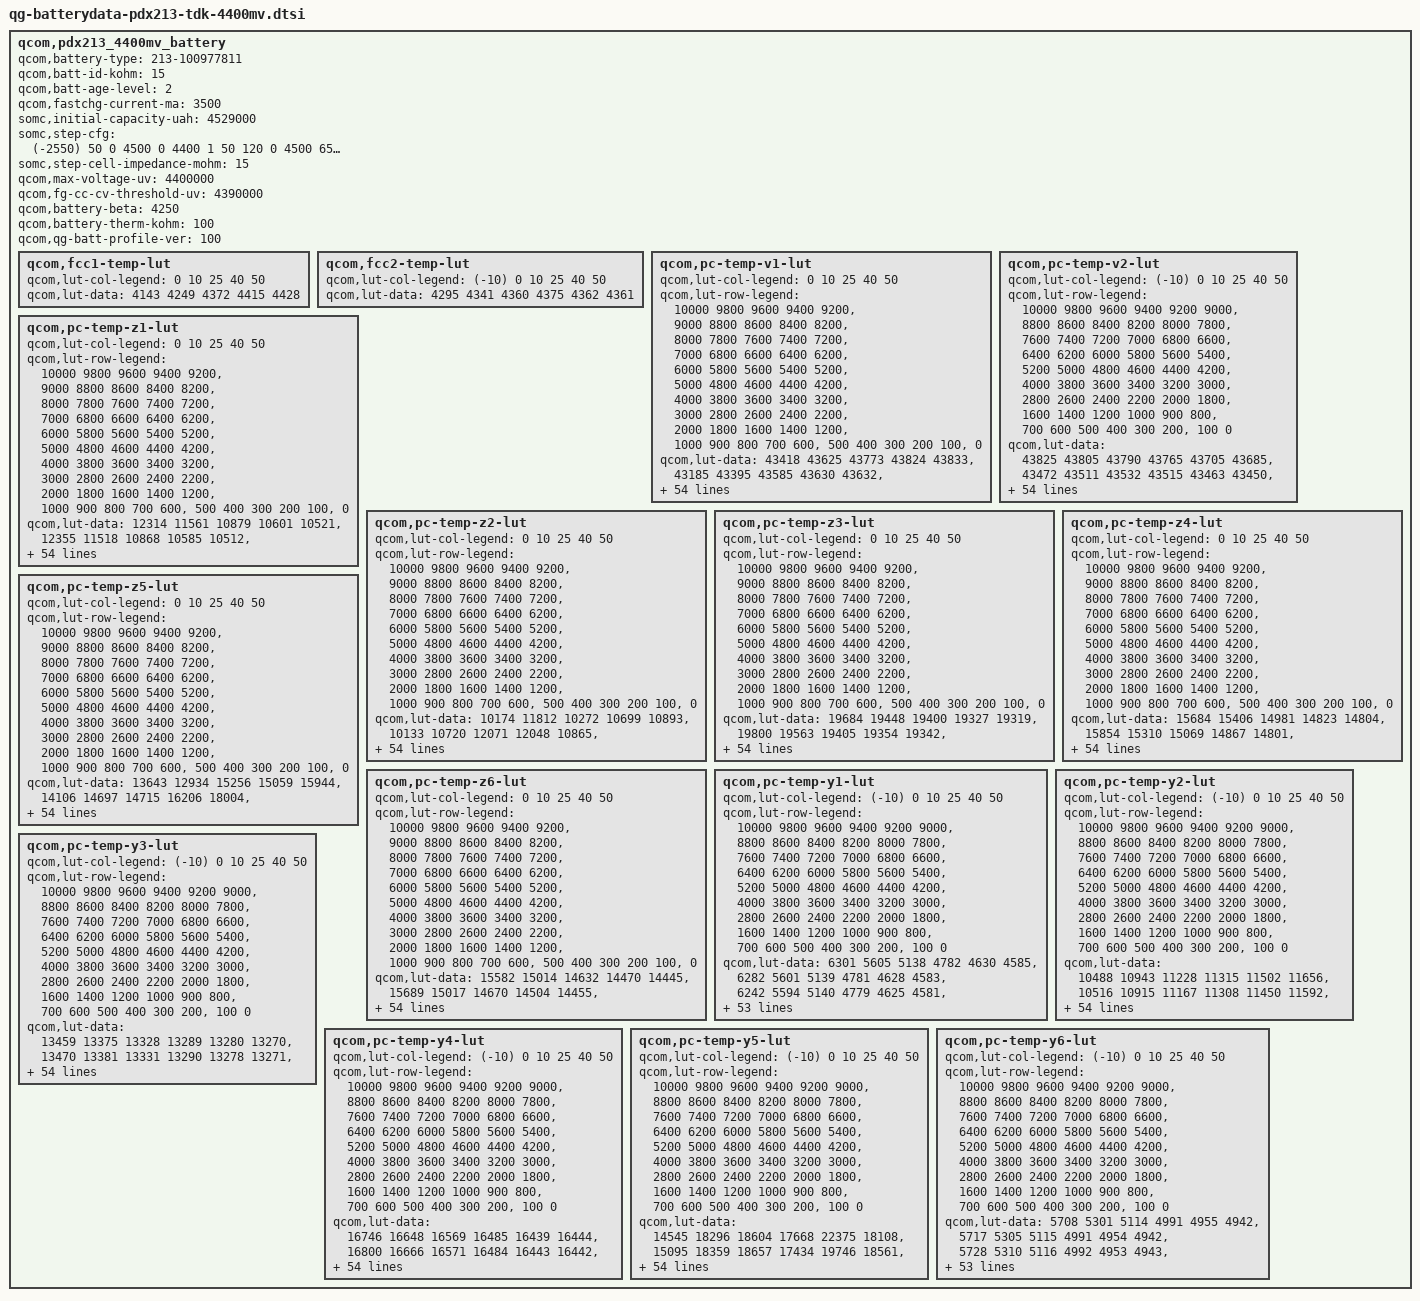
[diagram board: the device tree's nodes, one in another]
qcom,pdx213_4400mv_battery {
	/* Added or Modified by SOMC */
	qcom,battery-type = "213-100977811";
	qcom,batt-id-kohm = <15>;
	qcom,batt-age-level = <2>;
	qcom,fastchg-current-ma = <3500>;
	somc,initial-capacity-uah = <4529000>;
	somc,step-cfg = <
		(-2550) 50    0 4500    0 4400 1
		   50  120    0 4500  650 4400 2
		  120  150    0 4100 1950 4400 3
		  120  150 4100 4200 1500 4400 3
		  120  150 4200 4300 1300 4400 3
		  120  150 4300 4500  800 4400 3
		  150  200    0 4100 2400 4400 3
		  150  200 4100 4200 1950 4400 3
		  150  200 4200 4300 1750 4400 3
		  150  200 4300 4500 1050 4400 3
		  200  450    0 4200 3900 4400 3
		  200  450 4200 4250 3050 4400 3
		  200  450 4250 4350 1950 4400 3
		  200  450 4350 4500 1300 4400 3
		  450  550    0 4500 1300 4200 4
		  550 2550    0 4500    0 4200 5
	>;
	somc,step-cell-impedance-mohm = <15>;

	/* Prepared by Qualcomm */
    /* 4764141_SoMC_Licht_4314mAh_averaged_MasterSlave_Sept9th2020 */
    qcom,max-voltage-uv = <4400000>;
    qcom,fg-cc-cv-threshold-uv = <4390000>;
    /* qcom,fastchg-current-ma = <1500>; */
    /* qcom,batt-id-kohm = <0>; */
    qcom,battery-beta = <4250>;
    qcom,battery-therm-kohm = <100>;
    /* qcom,battery-type = "4764141_SoMC_Licht_4314mAh_averaged_MasterSlave_Sept9th2020"; */
    qcom,qg-batt-profile-ver = <100>;

	qcom,fcc1-temp-lut {
		qcom,lut-col-legend = <0 10 25 40 50>;
		qcom,lut-data = <4143 4249 4372 4415 4428>;
	};

	qcom,fcc2-temp-lut {
		qcom,lut-col-legend = <(-10) 0 10 25 40 50>;
		qcom,lut-data = <4295 4341 4360 4375 4362 4361>;
	};

	qcom,pc-temp-v1-lut {
		qcom,lut-col-legend = <0 10 25 40 50>;
		qcom,lut-row-legend = <10000 9800 9600 9400 9200>,
			<9000 8800 8600 8400 8200>,
			<8000 7800 7600 7400 7200>,
			<7000 6800 6600 6400 6200>,
			<6000 5800 5600 5400 5200>,
			<5000 4800 4600 4400 4200>,
			<4000 3800 3600 3400 3200>,
			<3000 2800 2600 2400 2200>,
			<2000 1800 1600 1400 1200>,
			<1000 900 800 700 600>,
			<500 400 300 200 100>,
			<0>;
		qcom,lut-data = <43418 43625 43773 43824 43833>,
			<43185 43395 43585 43630 43632>,
			<42957 43166 43369 43423 43431>,
			<42730 42937 43143 43201 43223>,
			<42504 42708 42913 42978 43006>,
			<42280 42479 42675 42750 42776>,
			<42059 42248 42440 42520 42543>,
			<41841 42022 42205 42287 42310>,
			<41628 41799 41975 42053 42077>,
			<41420 41581 41749 41824 41848>,
			<41216 41368 41527 41598 41622>,
			<41020 41160 41310 41377 41401>,
			<40834 40960 41095 41159 41183>,
			<40655 40771 40889 40947 40970>,
			<40473 40588 40689 40743 40765>,
			<40285 40407 40498 40545 40567>,
			<40110 40229 40317 40357 40377>,
			<39962 40059 40146 40181 40197>,
			<39829 39909 39980 40012 40024>,
			<39688 39763 39827 39851 39860>,
			<39534 39570 39669 39694 39704>,
			<39371 39294 39456 39510 39526>,
			<39188 39053 39176 39262 39286>,
			<38982 38913 38968 39035 39056>,
			<38818 38806 38855 38889 38901>,
			<38711 38718 38766 38774 38778>,
			<38628 38647 38671 38666 38667>,
			<38565 38582 38576 38565 38565>,
			<38516 38512 38489 38473 38472>,
			<38473 38442 38411 38388 38384>,
			<38429 38380 38341 38312 38302>,
			<38388 38321 38278 38242 38228>,
			<38347 38269 38223 38180 38160>,
			<38309 38223 38173 38122 38096>,
			<38271 38182 38129 38071 38040>,
			<38235 38143 38087 38021 37985>,
			<38201 38109 38044 37967 37919>,
			<38158 38071 38001 37910 37844>,
			<38088 38007 37941 37842 37763>,
			<37992 37906 37849 37758 37682>,
			<37885 37793 37739 37658 37591>,
			<37758 37671 37622 37542 37476>,
			<37614 37534 37487 37407 37337>,
			<37448 37371 37323 37252 37181>,
			<37305 37226 37175 37111 37045>,
			<37201 37129 37084 37022 36963>,
			<37171 37105 37059 37002 36941>,
			<37145 37081 37044 36985 36925>,
			<37114 37059 37025 36968 36911>,
			<37073 37029 36992 36932 36870>,
			<36931 36862 36802 36713 36625>,
			<36514 36438 36387 36293 36199>,
			<35954 35871 35829 35734 35640>,
			<35183 35090 35070 34976 34880>,
			<33848 33793 33910 33814 33719>,
			<30000 30000 30000 30000 30000>;
	};

	qcom,pc-temp-v2-lut {
		qcom,lut-col-legend = <(-10) 0 10 25 40 50>;
		qcom,lut-row-legend = <10000 9800 9600 9400 9200 9000>,
			<8800 8600 8400 8200 8000 7800>,
			<7600 7400 7200 7000 6800 6600>,
			<6400 6200 6000 5800 5600 5400>,
			<5200 5000 4800 4600 4400 4200>,
			<4000 3800 3600 3400 3200 3000>,
			<2800 2600 2400 2200 2000 1800>,
			<1600 1400 1200 1000 900 800>,
			<700 600 500 400 300 200>,
			<100 0>;
		qcom,lut-data = <43825 43805 43790 43765 43705 43685>,
			<43472 43511 43532 43515 43463 43450>,
			<43153 43235 43281 43272 43226 43217>,
			<42875 42976 43039 43035 42993 42988>,
			<42635 42736 42805 42805 42765 42761>,
			<42401 42500 42572 42575 42537 42535>,
			<42163 42262 42336 42342 42307 42305>,
			<41926 42027 42100 42108 42078 42074>,
			<41680 41797 41870 41879 41851 41847>,
			<41418 41571 41643 41653 41625 41622>,
			<41191 41352 41419 41429 41403 41401>,
			<41037 41140 41201 41210 41187 41186>,
			<40900 40936 40987 40995 40974 40975>,
			<40694 40746 40785 40789 40769 40771>,
			<40361 40569 40590 40589 40569 40571>,
			<40047 40373 40400 40396 40377 40379>,
			<39833 40133 40221 40208 40194 40195>,
			<39647 39877 40036 40028 40018 40019>,
			<39455 39647 39816 39862 39852 39853>,
			<39255 39433 39566 39706 39695 39696>,
			<39062 39232 39337 39516 39511 39512>,
			<38875 39040 39131 39254 39261 39267>,
			<38697 38863 38946 39003 39017 39028>,
			<38535 38706 38790 38833 38849 38859>,
			<38377 38564 38653 38695 38714 38723>,
			<38252 38432 38530 38573 38595 38603>,
			<38174 38308 38418 38466 38490 38499>,
			<38116 38195 38316 38368 38394 38403>,
			<38059 38095 38223 38277 38305 38312>,
			<38006 38004 38135 38193 38223 38227>,
			<37955 37938 38052 38116 38149 38150>,
			<37902 37894 37971 38043 38081 38080>,
			<37849 37857 37899 37977 38016 38013>,
			<37793 37823 37840 37919 37950 37946>,
			<37738 37793 37789 37866 37882 37879>,
			<37680 37758 37744 37804 37804 37793>,
			<37615 37719 37709 37734 37712 37679>,
			<37543 37673 37670 37658 37618 37565>,
			<37465 37604 37615 37580 37531 37474>,
			<37380 37511 37545 37498 37445 37390>,
			<37291 37405 37457 37407 37352 37298>,
			<37199 37278 37337 37305 37252 37198>,
			<37107 37134 37201 37182 37132 37078>,
			<37017 36976 37047 37040 36994 36940>,
			<36925 36851 36898 36914 36880 36830>,
			<36830 36759 36826 36878 36851 36801>,
			<36777 36724 36795 36861 36841 36789>,
			<36723 36687 36754 36840 36822 36774>,
			<36661 36640 36709 36811 36799 36750>,
			<36586 36556 36625 36731 36730 36666>,
			<36468 36353 36382 36462 36445 36352>,
			<36239 35911 35898 35965 35961 35865>,
			<35807 35219 35233 35314 35328 35227>,
			<35083 34162 34292 34410 34455 34348>,
			<33992 32628 32837 33130 33226 33135>,
			<32283 29756 29523 29671 29837 29789>;
	};

	qcom,pc-temp-z1-lut {
		qcom,lut-col-legend = <0 10 25 40 50>;
		qcom,lut-row-legend = <10000 9800 9600 9400 9200>,
			<9000 8800 8600 8400 8200>,
			<8000 7800 7600 7400 7200>,
			<7000 6800 6600 6400 6200>,
			<6000 5800 5600 5400 5200>,
			<5000 4800 4600 4400 4200>,
			<4000 3800 3600 3400 3200>,
			<3000 2800 2600 2400 2200>,
			<2000 1800 1600 1400 1200>,
			<1000 900 800 700 600>,
			<500 400 300 200 100>,
			<0>;
		qcom,lut-data = <12314 11561 10879 10601 10521>,
			<12355 11518 10868 10585 10512>,
			<12332 11489 10856 10580 10510>,
			<12303 11468 10848 10576 10505>,
			<12280 11451 10841 10572 10503>,
			<12258 11442 10836 10570 10503>,
			<12237 11435 10833 10569 10502>,
			<12204 11430 10831 10567 10501>,
			<12174 11427 10829 10566 10500>,
			<12162 11424 10825 10565 10499>,
			<12157 11422 10820 10564 10499>,
			<12155 11419 10819 10564 10499>,
			<12158 11416 10818 10565 10499>,
			<12165 11411 10818 10565 10499>,
			<12168 11405 10818 10565 10500>,
			<12170 11403 10818 10566 10502>,
			<12172 11405 10819 10566 10503>,
			<12168 11407 10820 10567 10504>,
			<12160 11410 10821 10567 10505>,
			<12155 11415 10823 10568 10506>,
			<12163 11420 10827 10569 10506>,
			<12172 11429 10831 10571 10507>,
			<12174 11436 10837 10574 10511>,
			<12177 11441 10843 10578 10515>,
			<12184 11448 10847 10582 10516>,
			<12197 11451 10851 10586 10518>,
			<12212 11452 10855 10588 10519>,
			<12217 11453 10859 10590 10521>,
			<12213 11458 10863 10592 10523>,
			<12213 11467 10867 10595 10525>,
			<12227 11470 10871 10598 10528>,
			<12249 11468 10875 10600 10529>,
			<12259 11467 10878 10602 10531>,
			<12249 11468 10882 10604 10532>,
			<12237 11472 10886 10607 10534>,
			<12238 11477 10890 10609 10535>,
			<12243 11494 10895 10612 10537>,
			<12251 11512 10899 10616 10539>,
			<12268 11521 10904 10618 10541>,
			<12295 11526 10909 10620 10543>,
			<12318 11532 10915 10622 10546>,
			<12346 11544 10922 10624 10547>,
			<12351 11554 10928 10627 10549>,
			<12321 11557 10932 10629 10550>,
			<12346 11573 10938 10631 10552>,
			<12386 11581 10943 10633 10554>,
			<12352 11581 10950 10632 10555>,
			<12338 11576 10946 10634 10555>,
			<12368 11587 10943 10636 10556>,
			<12386 11583 10960 10638 10556>,
			<12389 11606 10966 10643 10561>,
			<12390 11622 10982 10652 10568>,
			<12457 11645 11001 10664 10578>,
			<12511 11698 11028 10682 10593>,
			<12511 11698 11028 10682 10593>,
			<12511 11698 11028 10682 10593>;
	};

	qcom,pc-temp-z2-lut {
		qcom,lut-col-legend = <0 10 25 40 50>;
		qcom,lut-row-legend = <10000 9800 9600 9400 9200>,
			<9000 8800 8600 8400 8200>,
			<8000 7800 7600 7400 7200>,
			<7000 6800 6600 6400 6200>,
			<6000 5800 5600 5400 5200>,
			<5000 4800 4600 4400 4200>,
			<4000 3800 3600 3400 3200>,
			<3000 2800 2600 2400 2200>,
			<2000 1800 1600 1400 1200>,
			<1000 900 800 700 600>,
			<500 400 300 200 100>,
			<0>;
		qcom,lut-data = <10174 11812 10272 10699 10893>,
			<10133 10720 12071 12048 10865>,
			<10103 10327 11552 11807 10990>,
			<10081 10281 11011 10927 11403>,
			<10066 10250 10739 10774 11553>,
			<10055 10237 10543 11103 11575>,
			<10050 10229 10508 11322 11594>,
			<10048 10226 10520 11309 11602>,
			<10048 10246 10540 11288 11609>,
			<10054 10279 10634 11317 11600>,
			<10071 10298 10776 11454 11535>,
			<10088 10310 10820 11523 11486>,
			<10098 10326 10833 11400 11513>,
			<10108 10415 10846 11253 11558>,
			<10121 10524 10865 11255 11461>,
			<10140 10524 10888 11316 10995>,
			<10159 10438 10919 11330 10753>,
			<10169 10387 10964 11022 10761>,
			<10177 10393 10984 10712 10773>,
			<10187 10401 10849 10694 10793>,
			<10205 10413 10669 10694 10832>,
			<10226 10437 10629 10700 10880>,
			<10247 10453 10599 10770 11005>,
			<10271 10437 10586 10842 11110>,
			<10287 10404 10628 10862 11057>,
			<10296 10396 10680 10869 10910>,
			<10302 10409 10680 10844 10816>,
			<10304 10422 10657 10773 10738>,
			<10303 10424 10634 10719 10690>,
			<10302 10424 10602 10705 10686>,
			<10303 10426 10576 10699 10684>,
			<10306 10437 10585 10701 10694>,
			<10310 10450 10618 10709 10757>,
			<10317 10462 10646 10723 10825>,
			<10325 10475 10666 10784 10881>,
			<10332 10486 10686 10873 10939>,
			<10338 10495 10707 10948 11013>,
			<10344 10505 10731 11019 11129>,
			<10354 10520 10759 11051 11185>,
			<10363 10540 10800 11053 11176>,
			<10364 10549 10831 11051 11161>,
			<10355 10541 10831 11075 11168>,
			<10353 10535 10824 11116 11183>,
			<10372 10544 10837 11059 11141>,
			<10562 10624 10868 11016 11112>,
			<10583 10683 10862 10990 11094>,
			<10428 10744 10852 10976 11085>,
			<10272 10782 10827 10988 11037>,
			<10285 10954 10820 10963 11163>,
			<10276 11229 10813 11054 11280>,
			<10252 10935 11020 10903 10889>,
			<10094 10940 10964 10735 10733>,
			<9876 10858 10921 10699 10625>,
			<9741 10640 10829 10598 10582>,
			<9741 10640 10829 10598 10582>,
			<9741 10640 10829 10598 10582>;
	};

	qcom,pc-temp-z3-lut {
		qcom,lut-col-legend = <0 10 25 40 50>;
		qcom,lut-row-legend = <10000 9800 9600 9400 9200>,
			<9000 8800 8600 8400 8200>,
			<8000 7800 7600 7400 7200>,
			<7000 6800 6600 6400 6200>,
			<6000 5800 5600 5400 5200>,
			<5000 4800 4600 4400 4200>,
			<4000 3800 3600 3400 3200>,
			<3000 2800 2600 2400 2200>,
			<2000 1800 1600 1400 1200>,
			<1000 900 800 700 600>,
			<500 400 300 200 100>,
			<0>;
		qcom,lut-data = <19684 19448 19400 19327 19319>,
			<19800 19563 19405 19354 19342>,
			<19839 19613 19453 19376 19362>,
			<19856 19627 19488 19400 19374>,
			<19858 19635 19486 19411 19378>,
			<19858 19635 19481 19411 19376>,
			<19858 19630 19474 19409 19375>,
			<19855 19624 19463 19405 19374>,
			<19851 19612 19455 19399 19373>,
			<19842 19597 19452 19394 19371>,
			<19824 19587 19451 19387 19362>,
			<19807 19580 19450 19381 19355>,
			<19798 19576 19448 19377 19354>,
			<19789 19579 19446 19373 19353>,
			<19780 19583 19444 19372 19348>,
			<19765 19580 19441 19372 19334>,
			<19753 19568 19439 19370 19326>,
			<19746 19558 19436 19355 19326>,
			<19742 19552 19432 19340 19325>,
			<19741 19549 19423 19340 19324>,
			<19745 19552 19414 19342 19321>,
			<19751 19578 19415 19343 19321>,
			<19759 19598 19423 19342 19328>,
			<19768 19590 19426 19341 19340>,
			<19773 19573 19418 19353 19354>,
			<19771 19565 19407 19380 19372>,
			<19765 19561 19415 19390 19376>,
			<19759 19559 19445 19392 19370>,
			<19752 19564 19458 19393 19363>,
			<19745 19574 19456 19389 19358>,
			<19740 19577 19452 19380 19353>,
			<19736 19575 19447 19372 19347>,
			<19732 19571 19439 19365 19341>,
			<19729 19566 19432 19360 19336>,
			<19726 19561 19427 19355 19330>,
			<19722 19555 19422 19351 19325>,
			<19717 19551 19419 19350 19325>,
			<19711 19547 19416 19350 19328>,
			<19704 19542 19414 19350 19329>,
			<19696 19538 19411 19347 19327>,
			<19688 19533 19408 19345 19325>,
			<19679 19528 19403 19345 19325>,
			<19667 19522 19398 19346 19328>,
			<19647 19512 19398 19344 19334>,
			<19548 19482 19394 19340 19333>,
			<19486 19467 19379 19333 19316>,
			<19399 19436 19378 19326 19316>,
			<19327 19429 19369 19326 19317>,
			<19324 19379 19368 19324 19305>,
			<19319 19314 19367 19320 19301>,
			<19321 19379 19346 19344 19335>,
			<19325 19331 19354 19347 19339>,
			<19329 19330 19352 19354 19340>,
			<19349 19339 19366 19357 19344>,
			<19349 19339 19366 19357 19344>,
			<19349 19339 19366 19357 19344>;
	};

	qcom,pc-temp-z4-lut {
		qcom,lut-col-legend = <0 10 25 40 50>;
		qcom,lut-row-legend = <10000 9800 9600 9400 9200>,
			<9000 8800 8600 8400 8200>,
			<8000 7800 7600 7400 7200>,
			<7000 6800 6600 6400 6200>,
			<6000 5800 5600 5400 5200>,
			<5000 4800 4600 4400 4200>,
			<4000 3800 3600 3400 3200>,
			<3000 2800 2600 2400 2200>,
			<2000 1800 1600 1400 1200>,
			<1000 900 800 700 600>,
			<500 400 300 200 100>,
			<0>;
		qcom,lut-data = <15684 15406 14981 14823 14804>,
			<15854 15310 15069 14867 14801>,
			<15677 15218 14995 14868 14821>,
			<15477 15126 14909 14826 14776>,
			<15362 15042 14861 14790 14746>,
			<15269 14977 14823 14755 14730>,
			<15189 14922 14803 14732 14718>,
			<15120 14887 14794 14724 14709>,
			<15061 14868 14785 14718 14701>,
			<15011 14856 14768 14711 14696>,
			<14965 14845 14749 14704 14694>,
			<14937 14837 14736 14697 14690>,
			<14923 14828 14725 14691 14682>,
			<14914 14810 14716 14684 14672>,
			<14915 14791 14708 14676 14670>,
			<14931 14789 14702 14665 14675>,
			<14946 14795 14697 14661 14676>,
			<14929 14798 14692 14670 14669>,
			<14890 14791 14690 14679 14661>,
			<14874 14782 14697 14680 14660>,
			<14876 14793 14711 14681 14663>,
			<14881 14891 14755 14689 14670>,
			<14908 14972 14872 14777 14729>,
			<14993 14982 14931 14855 14788>,
			<15045 14988 14921 14837 14777>,
			<15048 14986 14901 14789 14741>,
			<15049 14956 14870 14758 14721>,
			<15047 14919 14819 14738 14712>,
			<15027 14891 14787 14723 14705>,
			<15001 14865 14772 14714 14698>,
			<14983 14850 14762 14707 14690>,
			<14966 14842 14756 14701 14683>,
			<14950 14836 14752 14696 14677>,
			<14936 14833 14751 14693 14674>,
			<14922 14832 14750 14694 14674>,
			<14910 14829 14750 14695 14676>,
			<14898 14820 14751 14699 14682>,
			<14886 14812 14753 14710 14702>,
			<14877 14811 14756 14718 14712>,
			<14867 14810 14764 14723 14709>,
			<14854 14809 14770 14727 14704>,
			<14834 14791 14762 14722 14699>,
			<14813 14770 14747 14713 14694>,
			<14791 14755 14739 14714 14692>,
			<14783 14724 14722 14708 14689>,
			<14815 14701 14699 14694 14683>,
			<14904 14717 14686 14686 14672>,
			<14978 14712 14672 14665 14652>,
			<14976 14760 14657 14647 14641>,
			<14975 14828 14656 14648 14642>,
			<14971 14761 14702 14653 14640>,
			<14985 14828 14699 14655 14641>,
			<14991 14835 14701 14648 14641>,
			<14997 14838 14687 14646 14638>,
			<14997 14838 14687 14646 14638>,
			<14997 14838 14687 14646 14638>;
	};

	qcom,pc-temp-z5-lut {
		qcom,lut-col-legend = <0 10 25 40 50>;
		qcom,lut-row-legend = <10000 9800 9600 9400 9200>,
			<9000 8800 8600 8400 8200>,
			<8000 7800 7600 7400 7200>,
			<7000 6800 6600 6400 6200>,
			<6000 5800 5600 5400 5200>,
			<5000 4800 4600 4400 4200>,
			<4000 3800 3600 3400 3200>,
			<3000 2800 2600 2400 2200>,
			<2000 1800 1600 1400 1200>,
			<1000 900 800 700 600>,
			<500 400 300 200 100>,
			<0>;
		qcom,lut-data = <13643 12934 15256 15059 15944>,
			<14106 14697 14715 16206 18004>,
			<14625 15754 15903 17236 18360>,
			<15132 16327 17286 18785 19266>,
			<15555 16838 18353 20148 20217>,
			<15945 17518 19320 21691 21263>,
			<16430 18348 19532 22471 22281>,
			<17102 18898 19386 22436 23223>,
			<17879 19211 19243 22449 24049>,
			<18734 19440 19513 22437 24112>,
			<19707 19535 20170 22211 23202>,
			<20387 19791 20838 22149 22517>,
			<20889 20115 21740 22580 23572>,
			<21327 21134 22685 23345 25257>,
			<21330 22357 23526 24687 24880>,
			<20761 22454 24315 26967 21933>,
			<20273 21843 25094 27733 20379>,
			<20491 21424 26030 24042 21456>,
			<21310 22253 26543 20266 22858>,
			<22601 24408 25649 20731 23062>,
			<26307 27805 24418 22524 23023>,
			<30852 35160 24280 22871 22765>,
			<33819 40158 24263 19375 19716>,
			<36328 36335 24026 16293 16660>,
			<37424 28238 20949 16532 17248>,
			<35982 24461 17373 17461 19288>,
			<33249 22956 17637 18609 20296>,
			<31302 22244 20131 20336 20498>,
			<29710 23106 22571 21791 20729>,
			<28732 25466 24628 22690 21432>,
			<28573 27525 26483 23562 22534>,
			<28545 29350 27965 24465 23672>,
			<28637 30750 29233 25481 25006>,
			<29185 31418 29988 26370 25851>,
			<29873 31875 30520 27647 26278>,
			<30210 31999 30822 28786 26604>,
			<30414 31848 30721 28720 26456>,
			<30608 31613 30323 27938 25587>,
			<30894 31432 29667 26841 24673>,
			<31162 31264 27985 24497 23286>,
			<31063 31020 26321 22554 22130>,
			<29822 30532 25479 22651 22266>,
			<28588 29823 24950 23010 22854>,
			<27452 28154 24784 21590 23457>,
			<21286 27526 25052 20555 22491>,
			<17520 26955 24387 20155 18528>,
			<14259 19697 25091 19447 19156>,
			<11913 18935 23333 21740 23443>,
			<11858 15480 24598 25153 22642>,
			<11803 12397 24583 23271 20624>,
			<11853 15340 16765 23379 28940>,
			<11824 12761 16677 23170 28556>,
			<11761 12634 16063 25047 27573>,
			<12206 12844 17215 25396 28730>,
			<12206 12844 17215 25396 28730>,
			<12206 12844 17215 25396 28730>;
	};

	qcom,pc-temp-z6-lut {
		qcom,lut-col-legend = <0 10 25 40 50>;
		qcom,lut-row-legend = <10000 9800 9600 9400 9200>,
			<9000 8800 8600 8400 8200>,
			<8000 7800 7600 7400 7200>,
			<7000 6800 6600 6400 6200>,
			<6000 5800 5600 5400 5200>,
			<5000 4800 4600 4400 4200>,
			<4000 3800 3600 3400 3200>,
			<3000 2800 2600 2400 2200>,
			<2000 1800 1600 1400 1200>,
			<1000 900 800 700 600>,
			<500 400 300 200 100>,
			<0>;
		qcom,lut-data = <15582 15014 14632 14470 14445>,
			<15689 15017 14670 14504 14455>,
			<15613 15003 14658 14514 14471>,
			<15524 14966 14640 14507 14461>,
			<15463 14922 14621 14500 14452>,
			<15410 14888 14598 14486 14444>,
			<15363 14858 14583 14473 14438>,
			<15321 14835 14573 14466 14433>,
			<15283 14818 14565 14461 14429>,
			<15247 14804 14555 14455 14424>,
			<15211 14793 14546 14448 14419>,
			<15188 14785 14539 14442 14414>,
			<15175 14778 14533 14436 14409>,
			<15166 14771 14528 14431 14404>,
			<15163 14765 14523 14427 14400>,
			<15161 14761 14519 14423 14395>,
			<15159 14757 14515 14418 14390>,
			<15150 14753 14511 14413 14386>,
			<15133 14748 14509 14410 14383>,
			<15127 14744 14510 14410 14383>,
			<15132 14752 14511 14411 14383>,
			<15142 14811 14527 14417 14385>,
			<15163 14856 14584 14456 14418>,
			<15207 14856 14613 14489 14450>,
			<15232 14853 14605 14488 14451>,
			<15233 14849 14593 14483 14446>,
			<15233 14835 14585 14477 14441>,
			<15231 14822 14579 14470 14434>,
			<15220 14815 14573 14463 14427>,
			<15208 14809 14567 14456 14421>,
			<15200 14805 14561 14449 14415>,
			<15194 14802 14556 14443 14410>,
			<15188 14799 14551 14436 14404>,
			<15184 14796 14547 14433 14400>,
			<15180 14794 14543 14430 14396>,
			<15177 14792 14541 14429 14394>,
			<15174 14789 14541 14430 14397>,
			<15172 14786 14542 14435 14407>,
			<15173 14787 14543 14438 14412>,
			<15174 14789 14546 14440 14410>,
			<15174 14790 14548 14440 14407>,
			<15170 14784 14544 14439 14406>,
			<15165 14777 14536 14436 14405>,
			<15159 14770 14534 14435 14407>,
			<15122 14750 14526 14431 14406>,
			<15111 14735 14509 14421 14394>,
			<15107 14728 14504 14415 14389>,
			<15105 14724 14494 14405 14382>,
			<15107 14722 14487 14396 14370>,
			<15109 14722 14487 14395 14369>,
			<15124 14735 14499 14411 14386>,
			<15147 14746 14505 14415 14391>,
			<15171 14761 14510 14418 14394>,
			<15216 14785 14518 14423 14398>,
			<15216 14785 14518 14423 14398>,
			<15216 14785 14518 14423 14398>;
	};

	qcom,pc-temp-y1-lut {
		qcom,lut-col-legend = <(-10) 0 10 25 40 50>;
		qcom,lut-row-legend = <10000 9800 9600 9400 9200 9000>,
			<8800 8600 8400 8200 8000 7800>,
			<7600 7400 7200 7000 6800 6600>,
			<6400 6200 6000 5800 5600 5400>,
			<5200 5000 4800 4600 4400 4200>,
			<4000 3800 3600 3400 3200 3000>,
			<2800 2600 2400 2200 2000 1800>,
			<1600 1400 1200 1000 900 800>,
			<700 600 500 400 300 200>,
			<100 0>;
		qcom,lut-data = <6301 5605 5138 4782 4630 4585>,
			<6282 5601 5139 4781 4628 4583>,
			<6242 5594 5140 4779 4625 4581>,
			<6194 5587 5140 4777 4622 4580>,
			<6154 5581 5140 4775 4619 4579>,
			<6136 5579 5140 4773 4618 4579>,
			<6136 5573 5139 4772 4617 4579>,
			<6136 5565 5137 4771 4617 4580>,
			<6139 5562 5134 4768 4617 4580>,
			<6155 5561 5130 4764 4616 4578>,
			<6167 5561 5126 4763 4616 4578>,
			<6177 5555 5121 4763 4615 4578>,
			<6193 5548 5117 4764 4615 4577>,
			<6198 5554 5117 4764 4615 4578>,
			<6200 5571 5119 4762 4616 4578>,
			<6202 5581 5120 4762 4616 4578>,
			<6201 5575 5121 4762 4615 4578>,
			<6195 5565 5121 4763 4615 4579>,
			<6186 5565 5122 4764 4615 4579>,
			<6162 5565 5122 4764 4617 4579>,
			<6146 5566 5123 4765 4618 4580>,
			<6161 5580 5127 4768 4619 4581>,
			<6188 5595 5131 4772 4620 4582>,
			<6193 5591 5132 4774 4621 4582>,
			<6183 5574 5134 4775 4622 4583>,
			<6174 5567 5136 4777 4623 4583>,
			<6174 5578 5140 4781 4624 4584>,
			<6179 5590 5144 4784 4625 4586>,
			<6180 5592 5146 4787 4626 4587>,
			<6176 5587 5146 4790 4627 4588>,
			<6170 5586 5146 4793 4629 4590>,
			<6172 5591 5150 4795 4631 4591>,
			<6182 5596 5154 4798 4633 4592>,
			<6184 5594 5152 4802 4635 4594>,
			<6189 5591 5149 4806 4637 4597>,
			<6195 5591 5149 4808 4639 4598>,
			<6187 5586 5161 4811 4640 4598>,
			<6170 5579 5172 4812 4641 4597>,
			<6167 5576 5173 4813 4642 4598>,
			<6188 5570 5173 4814 4644 4599>,
			<6208 5570 5175 4817 4644 4600>,
			<6212 5578 5189 4822 4645 4601>,
			<6215 5582 5199 4823 4646 4601>,
			<6215 5583 5205 4825 4647 4602>,
			<6197 5579 5199 4831 4648 4603>,
			<6170 5609 5208 4833 4651 4605>,
			<6187 5622 5213 4835 4651 4604>,
			<6244 5612 5198 4842 4652 4605>,
			<6306 5620 5213 4842 4653 4605>,
			<6305 5635 5207 4843 4653 4606>,
			<6361 5648 5211 4848 4654 4609>,
			<6415 5700 5229 4856 4658 4609>,
			<6517 5734 5235 4868 4662 4614>,
			<6508 5812 5286 4896 4671 4621>,
			<6508 5812 5286 4896 4671 4621>,
			<6508 5812 5286 4896 4671 4621>;
	};

	qcom,pc-temp-y2-lut {
		qcom,lut-col-legend = <(-10) 0 10 25 40 50>;
		qcom,lut-row-legend = <10000 9800 9600 9400 9200 9000>,
			<8800 8600 8400 8200 8000 7800>,
			<7600 7400 7200 7000 6800 6600>,
			<6400 6200 6000 5800 5600 5400>,
			<5200 5000 4800 4600 4400 4200>,
			<4000 3800 3600 3400 3200 3000>,
			<2800 2600 2400 2200 2000 1800>,
			<1600 1400 1200 1000 900 800>,
			<700 600 500 400 300 200>,
			<100 0>;
		qcom,lut-data = <10488 10943 11228 11315 11502 11656>,
			<10516 10915 11167 11308 11450 11592>,
			<10546 10883 11106 11292 11399 11529>,
			<10574 10853 11050 11271 11350 11471>,
			<10595 10828 11002 11247 11306 11418>,
			<10606 10811 10964 11226 11266 11371>,
			<10605 10800 10933 11199 11224 11329>,
			<10601 10793 10909 11170 11191 11292>,
			<10617 10791 10903 11151 11199 11257>,
			<10698 10794 10902 11133 11249 11222>,
			<10760 10799 10904 11127 11277 11209>,
			<10772 10823 10915 11131 11276 11265>,
			<10778 10859 10934 11140 11276 11340>,
			<10787 10890 10960 11154 11281 11363>,
			<10808 10932 11002 11182 11299 11373>,
			<10830 10965 11052 11215 11321 11380>,
			<10848 10991 11124 11260 11352 11385>,
			<10864 11016 11183 11312 11397 11395>,
			<10867 11030 11192 11375 11495 11460>,
			<10867 11040 11192 11447 11659 11624>,
			<10865 11050 11195 11467 11716 11689>,
			<10852 11059 11206 11436 11598 11637>,
			<10819 11067 11220 11407 11474 11584>,
			<10743 11079 11233 11417 11491 11611>,
			<10472 11094 11247 11447 11559 11693>,
			<10260 11100 11261 11470 11602 11728>,
			<10094 11089 11279 11486 11637 11730>,
			<9806 11077 11293 11504 11662 11731>,
			<9711 11097 11300 11535 11700 11778>,
			<9699 11161 11304 11570 11772 11881>,
			<9691 11188 11304 11582 11796 11935>,
			<9685 11147 11294 11583 11862 11954>,
			<9680 11085 11283 11585 11922 11973>,
			<9676 11033 11277 11593 11914 12030>,
			<9673 10978 11271 11601 11892 12117>,
			<9670 10928 11261 11597 11858 12136>,
			<9668 10892 11236 11572 11790 12091>,
			<9667 10847 11205 11546 11731 12037>,
			<9665 10669 11174 11527 11700 11964>,
			<9664 10347 11138 11510 11676 11868>,
			<9664 10167 11090 11500 11656 11839>,
			<9663 9861 11020 11492 11639 11845>,
			<9662 9690 10939 11469 11636 11834>,
			<9661 9680 10845 11423 11644 11800>,
			<9660 9674 10734 11408 11664 11728>,
			<9658 9669 10684 11354 11547 11566>,
			<9657 9666 10578 11361 11534 11498>,
			<9656 9664 10312 11358 11456 11426>,
			<9654 9661 10203 11314 11441 11455>,
			<9652 9658 10091 11306 11494 11439>,
			<9650 9654 9766 11275 11474 11354>,
			<9649 9651 9683 11203 11387 11305>,
			<9648 9649 9661 11085 11286 11207>,
			<9648 9649 9655 10966 11171 11097>,
			<9648 9649 9655 10966 11171 11097>,
			<9648 9649 9655 10966 11171 11097>;
	};

	qcom,pc-temp-y3-lut {
		qcom,lut-col-legend = <(-10) 0 10 25 40 50>;
		qcom,lut-row-legend = <10000 9800 9600 9400 9200 9000>,
			<8800 8600 8400 8200 8000 7800>,
			<7600 7400 7200 7000 6800 6600>,
			<6400 6200 6000 5800 5600 5400>,
			<5200 5000 4800 4600 4400 4200>,
			<4000 3800 3600 3400 3200 3000>,
			<2800 2600 2400 2200 2000 1800>,
			<1600 1400 1200 1000 900 800>,
			<700 600 500 400 300 200>,
			<100 0>;
		qcom,lut-data = <13459 13375 13328 13289 13280 13270>,
			<13470 13381 13331 13290 13278 13271>,
			<13484 13387 13334 13291 13277 13272>,
			<13498 13392 13336 13293 13277 13273>,
			<13508 13396 13339 13294 13278 13274>,
			<13513 13400 13341 13295 13279 13275>,
			<13511 13403 13342 13296 13281 13276>,
			<13508 13405 13344 13297 13285 13277>,
			<13505 13405 13345 13299 13286 13277>,
			<13501 13403 13346 13302 13287 13278>,
			<13498 13401 13347 13303 13288 13278>,
			<13489 13401 13346 13303 13288 13281>,
			<13474 13401 13345 13304 13289 13284>,
			<13470 13399 13344 13304 13288 13284>,
			<13470 13395 13344 13307 13288 13285>,
			<13468 13390 13345 13308 13288 13285>,
			<13462 13389 13347 13305 13289 13285>,
			<13453 13387 13349 13302 13291 13285>,
			<13445 13383 13347 13303 13291 13286>,
			<13438 13378 13340 13306 13292 13287>,
			<13431 13372 13334 13307 13291 13287>,
			<13426 13368 13330 13301 13286 13281>,
			<13422 13364 13326 13296 13280 13275>,
			<13414 13361 13324 13294 13279 13273>,
			<13395 13357 13322 13293 13278 13272>,
			<13382 13355 13321 13292 13278 13272>,
			<13386 13352 13321 13292 13277 13273>,
			<13396 13349 13320 13291 13277 13274>,
			<13408 13341 13320 13292 13277 13273>,
			<13424 13326 13319 13292 13277 13272>,
			<13443 13320 13318 13292 13277 13272>,
			<13463 13326 13318 13292 13278 13272>,
			<13486 13335 13318 13291 13278 13272>,
			<13515 13342 13317 13292 13278 13273>,
			<13554 13351 13317 13292 13278 13274>,
			<13599 13358 13317 13292 13278 13275>,
			<13648 13363 13320 13292 13277 13273>,
			<13702 13368 13323 13292 13276 13272>,
			<13761 13375 13326 13291 13276 13272>,
			<13826 13383 13329 13290 13275 13272>,
			<13896 13394 13330 13290 13276 13273>,
			<13969 13414 13331 13290 13276 13274>,
			<14050 13441 13333 13291 13277 13275>,
			<14143 13477 13335 13291 13277 13275>,
			<14260 13537 13336 13290 13274 13271>,
			<14339 13574 13337 13293 13278 13274>,
			<14425 13649 13341 13295 13281 13278>,
			<14692 13748 13344 13298 13283 13283>,
			<15110 13898 13359 13305 13289 13284>,
			<15837 14133 13386 13309 13290 13283>,
			<17232 14691 13429 13306 13286 13280>,
			<20402 16235 13530 13307 13285 13280>,
			<29604 21423 13905 13313 13286 13282>,
			<65535 44381 15555 13323 13289 13285>,
			<65535 44381 15555 13323 13289 13285>,
			<65535 44381 15555 13323 13289 13285>;
	};

	qcom,pc-temp-y4-lut {
		qcom,lut-col-legend = <(-10) 0 10 25 40 50>;
		qcom,lut-row-legend = <10000 9800 9600 9400 9200 9000>,
			<8800 8600 8400 8200 8000 7800>,
			<7600 7400 7200 7000 6800 6600>,
			<6400 6200 6000 5800 5600 5400>,
			<5200 5000 4800 4600 4400 4200>,
			<4000 3800 3600 3400 3200 3000>,
			<2800 2600 2400 2200 2000 1800>,
			<1600 1400 1200 1000 900 800>,
			<700 600 500 400 300 200>,
			<100 0>;
		qcom,lut-data = <16746 16648 16569 16485 16439 16444>,
			<16800 16666 16571 16484 16443 16442>,
			<16858 16689 16576 16483 16446 16440>,
			<16913 16712 16580 16483 16448 16439>,
			<16960 16732 16584 16483 16449 16439>,
			<16992 16743 16586 16484 16450 16439>,
			<17011 16747 16587 16485 16448 16440>,
			<17024 16750 16588 16488 16447 16442>,
			<17028 16757 16590 16489 16447 16445>,
			<17021 16771 16597 16491 16450 16448>,
			<17019 16788 16606 16494 16454 16451>,
			<17087 16806 16620 16501 16459 16451>,
			<17194 16828 16640 16511 16465 16451>,
			<17193 16859 16666 16519 16472 16453>,
			<17034 16903 16701 16528 16481 16460>,
			<16906 16922 16719 16540 16490 16467>,
			<16885 16870 16726 16562 16499 16475>,
			<16871 16789 16729 16588 16508 16484>,
			<16853 16746 16713 16611 16527 16499>,
			<16821 16717 16658 16633 16555 16520>,
			<16783 16690 16612 16634 16564 16526>,
			<16733 16661 16577 16567 16522 16497>,
			<16682 16635 16551 16498 16474 16463>,
			<16670 16616 16539 16483 16460 16452>,
			<16687 16602 16532 16475 16453 16447>,
			<16703 16586 16529 16474 16451 16445>,
			<16717 16564 16528 16477 16456 16448>,
			<16737 16547 16527 16482 16463 16453>,
			<16746 16551 16527 16487 16470 16459>,
			<16748 16566 16527 16494 16480 16468>,
			<16750 16572 16526 16501 16489 16478>,
			<16755 16573 16517 16509 16501 16488>,
			<16761 16573 16510 16517 16509 16495>,
			<16764 16577 16511 16526 16510 16498>,
			<16765 16592 16514 16533 16510 16499>,
			<16766 16608 16520 16532 16507 16497>,
			<16767 16629 16536 16517 16492 16478>,
			<16769 16652 16556 16502 16477 16462>,
			<16770 16672 16572 16492 16469 16459>,
			<16767 16690 16587 16484 16464 16457>,
			<16764 16698 16593 16484 16463 16456>,
			<16767 16702 16595 16487 16463 16456>,
			<16775 16699 16595 16490 16463 16455>,
			<16786 16670 16591 16489 16459 16451>,
			<16798 16662 16573 16470 16442 16435>,
			<16779 16657 16560 16475 16449 16443>,
			<16786 16668 16580 16486 16455 16447>,
			<16847 16690 16616 16503 16464 16454>,
			<16953 16723 16651 16521 16484 16497>,
			<17132 16763 16695 16543 16526 16530>,
			<17460 16867 16725 16525 16471 16458>,
			<18190 17265 16728 16506 16450 16445>,
			<21028 19895 16821 16530 16457 16451>,
			<46182 51092 18208 16582 16481 16475>,
			<46182 51092 18208 16582 16481 16475>,
			<46182 51092 18208 16582 16481 16475>;
	};

	qcom,pc-temp-y5-lut {
		qcom,lut-col-legend = <(-10) 0 10 25 40 50>;
		qcom,lut-row-legend = <10000 9800 9600 9400 9200 9000>,
			<8800 8600 8400 8200 8000 7800>,
			<7600 7400 7200 7000 6800 6600>,
			<6400 6200 6000 5800 5600 5400>,
			<5200 5000 4800 4600 4400 4200>,
			<4000 3800 3600 3400 3200 3000>,
			<2800 2600 2400 2200 2000 1800>,
			<1600 1400 1200 1000 900 800>,
			<700 600 500 400 300 200>,
			<100 0>;
		qcom,lut-data = <14545 18296 18604 17668 22375 18108>,
			<15095 18359 18657 17434 19746 18561>,
			<16033 18366 18610 17192 18099 18788>,
			<17068 18335 18480 16951 17205 18845>,
			<17910 18283 18287 16723 16838 18785>,
			<18266 18227 18049 16517 16777 18664>,
			<18214 18147 17743 16282 18081 18424>,
			<18125 18015 17374 16026 19865 18060>,
			<18030 17780 16963 15921 19999 17593>,
			<17636 17303 16480 16142 19402 16943>,
			<17374 16893 16042 16128 18691 16669>,
			<18138 16603 15578 15533 17927 17670>,
			<19403 16399 15219 14945 17094 18915>,
			<19882 16755 15226 14876 16232 18766>,
			<21240 18441 15519 14880 15305 17665>,
			<22257 19971 16065 14846 14946 16846>,
			<22160 20989 19098 14380 14938 16262>,
			<22008 21767 22443 13907 14942 15841>,
			<22191 22178 23132 14767 15072 15869>,
			<22556 22503 23409 17420 15569 16085>,
			<22874 22659 23458 19440 16319 16528>,
			<23103 22724 22984 21039 18615 18292>,
			<23282 22768 22433 21974 20621 19944>,
			<22605 22785 22224 21872 20707 19719>,
			<17378 22856 22058 21535 20624 18845>,
			<13108 22896 22021 21190 20414 18508>,
			<12701 22767 22167 20711 19297 18604>,
			<12492 22438 22405 20404 18161 18684>,
			<12469 20499 22768 20589 17733 18019>,
			<12610 15663 23240 20965 17435 16551>,
			<12777 13664 23521 21081 17393 16094>,
			<12876 14391 24088 20940 17816 16210>,
			<12964 15540 24477 20893 18376 16436>,
			<13120 16765 23639 21704 18874 17417>,
			<13471 18397 22080 23030 19426 19090>,
			<13767 19622 21543 23606 19823 19507>,
			<13864 20539 21597 23927 20177 19108>,
			<13919 21093 21614 24037 20350 18781>,
			<13904 20379 21424 22842 19993 18985>,
			<13797 18602 21118 20918 19366 19515>,
			<13638 17717 20592 19988 19168 20147>,
			<13378 16153 19489 19441 19154 21062>,
			<13090 14928 19150 19206 19399 22358>,
			<13049 14356 19116 19541 20473 23802>,
			<13075 14178 18635 19956 19757 20995>,
			<13316 13773 18756 20759 18571 17801>,
			<13224 13947 17570 19087 18481 18692>,
			<12920 13986 15686 17698 17929 22566>,
			<12367 14043 15320 18444 21776 21760>,
			<11740 14071 15491 19576 20316 18590>,
			<11008 13375 14538 20273 20667 20748>,
			<10116 11302 14150 22659 23412 23923>,
			<9287 9621 13718 23066 23415 24133>,
			<8878 8923 10556 23520 25146 26498>,
			<8878 8923 10556 23520 25146 26498>,
			<8878 8923 10556 23520 25146 26498>;
	};

	qcom,pc-temp-y6-lut {
		qcom,lut-col-legend = <(-10) 0 10 25 40 50>;
		qcom,lut-row-legend = <10000 9800 9600 9400 9200 9000>,
			<8800 8600 8400 8200 8000 7800>,
			<7600 7400 7200 7000 6800 6600>,
			<6400 6200 6000 5800 5600 5400>,
			<5200 5000 4800 4600 4400 4200>,
			<4000 3800 3600 3400 3200 3000>,
			<2800 2600 2400 2200 2000 1800>,
			<1600 1400 1200 1000 900 800>,
			<700 600 500 400 300 200>,
			<100 0>;
		qcom,lut-data = <5708 5301 5114 4991 4955 4942>,
			<5717 5305 5115 4991 4954 4942>,
			<5728 5310 5116 4992 4953 4943>,
			<5740 5315 5117 4992 4953 4943>,
			<5749 5319 5118 4993 4954 4944>,
			<5753 5321 5118 4994 4955 4945>,
			<5752 5321 5118 4995 4956 4946>,
			<5750 5321 5118 4996 4958 4947>,
			<5747 5321 5119 4997 4959 4948>,
			<5741 5322 5120 4999 4961 4949>,
			<5737 5323 5121 5001 4962 4951>,
			<5751 5326 5124 5004 4964 4953>,
			<5774 5331 5128 5006 4966 4955>,
			<5773 5337 5134 5009 4968 4956>,
			<5734 5346 5143 5013 4970 4958>,
			<5701 5351 5148 5017 4973 4960>,
			<5694 5336 5152 5022 4976 4963>,
			<5689 5312 5154 5027 4980 4966>,
			<5684 5297 5148 5034 4986 4970>,
			<5675 5286 5127 5042 4994 4977>,
			<5667 5277 5110 5043 4996 4979>,
			<5659 5267 5097 5020 4980 4966>,
			<5653 5260 5088 4996 4962 4951>,
			<5650 5255 5084 4991 4957 4947>,
			<5648 5252 5081 4988 4954 4944>,
			<5647 5249 5080 4988 4954 4944>,
			<5656 5246 5081 4989 4955 4945>,
			<5677 5243 5081 4990 4956 4947>,
			<5699 5243 5082 4992 4959 4949>,
			<5724 5244 5084 4994 4961 4951>,
			<5752 5246 5084 4997 4964 4953>,
			<5782 5257 5083 4999 4968 4956>,
			<5816 5273 5082 5002 4971 4959>,
			<5852 5291 5083 5005 4972 4961>,
			<5893 5314 5086 5008 4972 4962>,
			<5937 5341 5091 5008 4971 4961>,
			<5983 5371 5100 5004 4966 4955>,
			<6032 5404 5112 5000 4962 4949>,
			<6084 5436 5123 4997 4959 4949>,
			<6140 5469 5135 4995 4957 4949>,
			<6202 5503 5147 4995 4957 4949>,
			<6269 5540 5159 4997 4958 4950>,
			<6344 5580 5174 4999 4958 4950>,
			<6431 5627 5192 5000 4957 4949>,
			<6540 5698 5204 4995 4951 4942>,
			<6611 5752 5208 4999 4956 4947>,
			<6700 5829 5236 5004 4960 4950>,
			<6966 5928 5272 5011 4964 4956>,
			<7368 6074 5326 5022 4975 4969>,
			<8024 6299 5398 5032 4987 4978>,
			<9224 6830 5480 5026 4968 4955>,
			<11810 8197 5625 5023 4962 4952>,
			<19065 12716 6036 5039 4966 4956>,
			<49920 36972 7804 5067 4976 4966>,
			<49920 36972 7804 5067 4976 4966>,
			<49920 36972 7804 5067 4976 4966>;
	};

};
